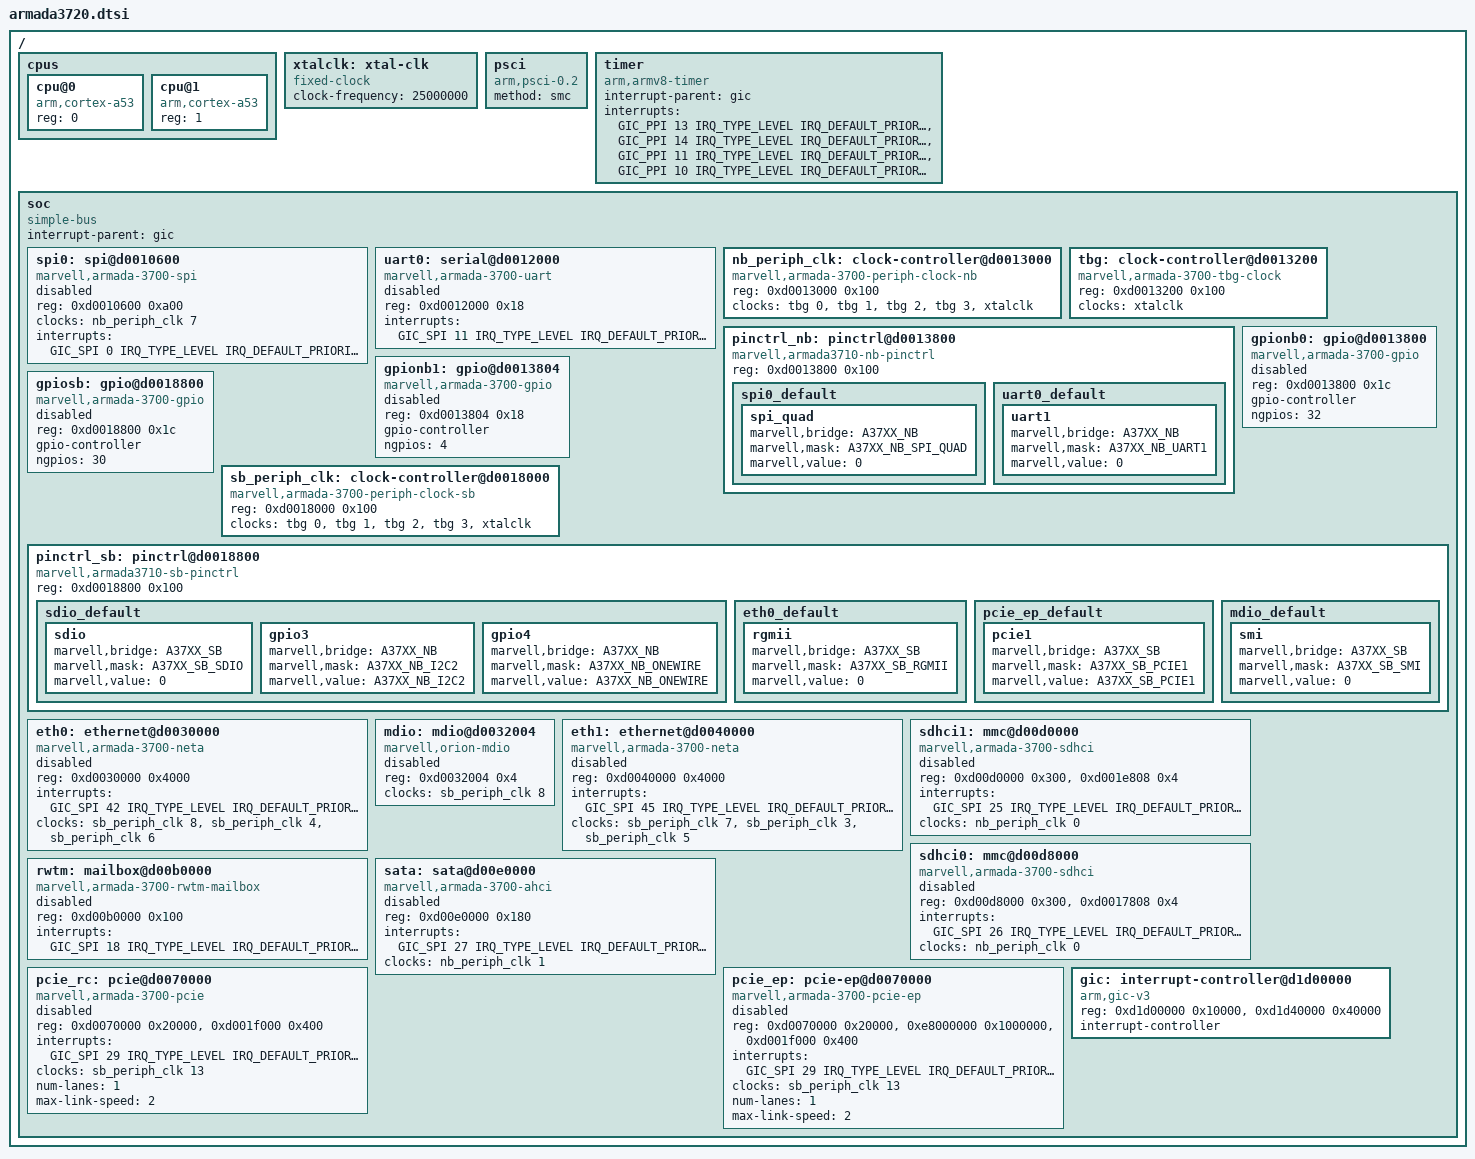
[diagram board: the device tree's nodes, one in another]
/*
 * Copyright (c) 2026 Jiri Kastner
 *
 * SPDX-License-Identifier: Apache-2.0
 *
 * Marvell Armada 3720. Internal registers at 0xd0000000 (32 MiB).
 * Addresses and interrupt numbers follow Linux armada-37xx.dtsi.
 */

#include <arm64/armv8-a.dtsi>
#include <mem.h>
#include <zephyr/dt-bindings/interrupt-controller/arm-gic.h>
#include <zephyr/dt-bindings/pinctrl/armada37xx-pinctrl.h>

/ {
	#address-cells = <1>;
	#size-cells = <1>;

	cpus {
		#address-cells = <1>;
		#size-cells = <0>;

		cpu@0 {
			device_type = "cpu";
			compatible = "arm,cortex-a53";
			reg = <0>;
		};

		cpu@1 {
			device_type = "cpu";
			compatible = "arm,cortex-a53";
			reg = <1>;
		};
	};

	/* 25 MHz on most boards; 40 MHz if strapped (NB GPIO1 latch bit 9) */
	xtalclk: xtal-clk {
		compatible = "fixed-clock";
		clock-frequency = <25000000>;
		#clock-cells = <0>;
	};

	psci: psci {
		compatible = "arm,psci-0.2";
		method = "smc";
	};

	timer {
		compatible = "arm,armv8-timer";
		interrupt-parent = <&gic>;
		interrupts = <GIC_PPI 13 IRQ_TYPE_LEVEL IRQ_DEFAULT_PRIORITY>,
			     <GIC_PPI 14 IRQ_TYPE_LEVEL IRQ_DEFAULT_PRIORITY>,
			     <GIC_PPI 11 IRQ_TYPE_LEVEL IRQ_DEFAULT_PRIORITY>,
			     <GIC_PPI 10 IRQ_TYPE_LEVEL IRQ_DEFAULT_PRIORITY>;
	};

	soc {
		#address-cells = <1>;
		#size-cells = <1>;
		compatible = "simple-bus";
		interrupt-parent = <&gic>;
		ranges;

		spi0: spi@d0010600 {
			compatible = "marvell,armada-3700-spi";
			reg = <0xd0010600 0xa00>;
			#address-cells = <1>;
			#size-cells = <0>;
			/* sqf */
			clocks = <&nb_periph_clk 7>;
			interrupts = <GIC_SPI 0 IRQ_TYPE_LEVEL IRQ_DEFAULT_PRIORITY>;
			status = "disabled";
		};

		uart0: serial@d0012000 {
			compatible = "marvell,armada-3700-uart";
			reg = <0xd0012000 0x18>;
			interrupts = <GIC_SPI 11 IRQ_TYPE_LEVEL IRQ_DEFAULT_PRIORITY>;
			interrupt-names = "uart-sum";
			status = "disabled";
		};

		nb_periph_clk: clock-controller@d0013000 {
			compatible = "marvell,armada-3700-periph-clock-nb";
			reg = <0xd0013000 0x100>;
			clocks = <&tbg 0>, <&tbg 1>, <&tbg 2>, <&tbg 3>, <&xtalclk>;
			#clock-cells = <1>;
		};

		tbg: clock-controller@d0013200 {
			compatible = "marvell,armada-3700-tbg-clock";
			reg = <0xd0013200 0x100>;
			clocks = <&xtalclk>;
			#clock-cells = <1>;
		};

		pinctrl_nb: pinctrl@d0013800 {
			compatible = "marvell,armada3710-nb-pinctrl";
			reg = <0xd0013800 0x100>;
		};

		/* GPIO banks of the pin controllers: pins 0..31, 32..35 (NB) */
		gpionb0: gpio@d0013800 {
			compatible = "marvell,armada-3700-gpio";
			reg = <0xd0013800 0x1c>;
			gpio-controller;
			#gpio-cells = <2>;
			ngpios = <32>;
			status = "disabled";
		};

		gpionb1: gpio@d0013804 {
			compatible = "marvell,armada-3700-gpio";
			reg = <0xd0013804 0x18>;
			gpio-controller;
			#gpio-cells = <2>;
			ngpios = <4>;
			status = "disabled";
		};

		gpiosb: gpio@d0018800 {
			compatible = "marvell,armada-3700-gpio";
			reg = <0xd0018800 0x1c>;
			gpio-controller;
			#gpio-cells = <2>;
			ngpios = <30>;
			status = "disabled";
		};

		sb_periph_clk: clock-controller@d0018000 {
			compatible = "marvell,armada-3700-periph-clock-sb";
			reg = <0xd0018000 0x100>;
			clocks = <&tbg 0>, <&tbg 1>, <&tbg 2>, <&tbg 3>, <&xtalclk>;
			#clock-cells = <1>;
		};

		pinctrl_sb: pinctrl@d0018800 {
			compatible = "marvell,armada3710-sb-pinctrl";
			reg = <0xd0018800 0x100>;
		};

		eth0: ethernet@d0030000 {
			compatible = "marvell,armada-3700-neta";
			reg = <0xd0030000 0x4000>;
			interrupts = <GIC_SPI 42 IRQ_TYPE_LEVEL IRQ_DEFAULT_PRIORITY>;
			/* gbe0_core, gbe0_50, gbe0_125 */
			clocks = <&sb_periph_clk 8>, <&sb_periph_clk 4>, <&sb_periph_clk 6>;
			status = "disabled";
		};

		mdio: mdio@d0032004 {
			compatible = "marvell,orion-mdio";
			reg = <0xd0032004 0x4>;
			/* the SMI register is part of the GbE0 block */
			clocks = <&sb_periph_clk 8>;
			#address-cells = <1>;
			#size-cells = <0>;
			status = "disabled";
		};

		eth1: ethernet@d0040000 {
			compatible = "marvell,armada-3700-neta";
			reg = <0xd0040000 0x4000>;
			interrupts = <GIC_SPI 45 IRQ_TYPE_LEVEL IRQ_DEFAULT_PRIORITY>;
			/* gbe1_core, gbe1_50, gbe1_125 */
			clocks = <&sb_periph_clk 7>, <&sb_periph_clk 3>, <&sb_periph_clk 5>;
			status = "disabled";
		};

		/* SD/SDIO slot; second register: SoC pad voltage */
		sdhci1: mmc@d00d0000 {
			compatible = "marvell,armada-3700-sdhci";
			reg = <0xd00d0000 0x300>, <0xd001e808 0x4>;
			reg-names = "base", "pad";
			interrupts = <GIC_SPI 25 IRQ_TYPE_LEVEL IRQ_DEFAULT_PRIORITY>;
			/* mmc */
			clocks = <&nb_periph_clk 0>;
			status = "disabled";
		};

		/* eMMC slot */
		sdhci0: mmc@d00d8000 {
			compatible = "marvell,armada-3700-sdhci";
			reg = <0xd00d8000 0x300>, <0xd0017808 0x4>;
			reg-names = "base", "pad";
			interrupts = <GIC_SPI 26 IRQ_TYPE_LEVEL IRQ_DEFAULT_PRIORITY>;
			clocks = <&nb_periph_clk 0>;
			status = "disabled";
		};

		/* rWTM mailbox to the Cortex-M3 secure processor */
		rwtm: mailbox@d00b0000 {
			compatible = "marvell,armada-3700-rwtm-mailbox";
			reg = <0xd00b0000 0x100>;
			interrupts = <GIC_SPI 18 IRQ_TYPE_LEVEL IRQ_DEFAULT_PRIORITY>;
			#mbox-cells = <1>;
			status = "disabled";
		};

		/* PCIe in endpoint mode; mem: AXI range decoded to PCIe for
		 * outbound windows (0xe8000000..0xefffffff, power of two used)
		 */
		/* SATA 3.0 AHCI host, PHY on COMPHY lane 2 (indirect window +0x178) */
		sata: sata@d00e0000 {
			compatible = "marvell,armada-3700-ahci";
			reg = <0xd00e0000 0x180>;
			interrupts = <GIC_SPI 27 IRQ_TYPE_LEVEL IRQ_DEFAULT_PRIORITY>;
			clocks = <&nb_periph_clk 1>;
			status = "disabled";
		};

		/* The same controller as root complex, see pcie_ep */
		pcie_rc: pcie@d0070000 {
			compatible = "marvell,armada-3700-pcie";
			reg = <0xd0070000 0x20000>, <0xd001f000 0x400>;
			reg-names = "ctrl", "comphy";
			interrupts = <GIC_SPI 29 IRQ_TYPE_LEVEL IRQ_DEFAULT_PRIORITY>;
			clocks = <&sb_periph_clk 13>;
			device_type = "pci";
			#address-cells = <3>;
			#size-cells = <2>;
			/* 0xe8000000-0xefffffff is decoded to PCIe; I/O not used yet */
			ranges = <0x82000000 0 0xe8000000 0xe8000000 0 0x07f00000>;
			num-lanes = <1>;
			max-link-speed = <2>;
			status = "disabled";
		};

		pcie_ep: pcie-ep@d0070000 {
			compatible = "marvell,armada-3700-pcie-ep";
			reg = <0xd0070000 0x20000>, <0xe8000000 0x1000000>,
			      <0xd001f000 0x400>;
			reg-names = "ctrl", "mem", "comphy";
			interrupts = <GIC_SPI 29 IRQ_TYPE_LEVEL IRQ_DEFAULT_PRIORITY>;
			/* pcie */
			clocks = <&sb_periph_clk 13>;
			num-lanes = <1>;
			max-link-speed = <2>;
			#address-cells = <1>;
			#size-cells = <0>;
			status = "disabled";
		};

		gic: interrupt-controller@d1d00000 {
			compatible = "arm,gic-v3", "arm,gic";
			reg = <0xd1d00000 0x10000>, /* GICD */
			      <0xd1d40000 0x40000>; /* GICR, 2 frames */
			interrupt-controller;
			#interrupt-cells = <4>;
			status = "okay";
		};
	};
};

&pinctrl_nb {
	/* CLK, MOSI, MISO and CS0 are dedicated; IO2/IO3 (WP#/HOLD#) are muxed */
	spi0_default: spi0_default {
		spi_quad {
			marvell,bridge = <A37XX_NB>;
			marvell,mask = <A37XX_NB_SPI_QUAD>;
			marvell,value = <0>;
		};
	};

	uart0_default: uart0_default {
		uart1 {
			marvell,bridge = <A37XX_NB>;
			marvell,mask = <A37XX_NB_UART1>;
			marvell,value = <0>;
		};
	};
};

&pinctrl_sb {
	/* SD slot on the south bridge pins; NB GPIO 3 (card detect) and 4
	 * (IO voltage) as GPIO
	 */
	sdio_default: sdio_default {
		sdio {
			marvell,bridge = <A37XX_SB>;
			marvell,mask = <A37XX_SB_SDIO>;
			marvell,value = <0>;
		};
		gpio3 {
			marvell,bridge = <A37XX_NB>;
			marvell,mask = <A37XX_NB_I2C2>;
			marvell,value = <A37XX_NB_I2C2>;
		};
		gpio4 {
			marvell,bridge = <A37XX_NB>;
			marvell,mask = <A37XX_NB_ONEWIRE>;
			marvell,value = <A37XX_NB_ONEWIRE>;
		};
	};

	eth0_default: eth0_default {
		rgmii {
			marvell,bridge = <A37XX_SB>;
			marvell,mask = <A37XX_SB_RGMII>;
			marvell,value = <0>;
		};
	};

	/* PCIe endpoint: PCIE1_RESETn (MPP2_3) as GPIO, PERST# comes in */
	pcie_ep_default: pcie_ep_default {
		pcie1 {
			marvell,bridge = <A37XX_SB>;
			marvell,mask = <A37XX_SB_PCIE1>;
			marvell,value = <A37XX_SB_PCIE1>;
		};
	};

	mdio_default: mdio_default {
		smi {
			marvell,bridge = <A37XX_SB>;
			marvell,mask = <A37XX_SB_SMI>;
			marvell,value = <0>;
		};
	};
};
